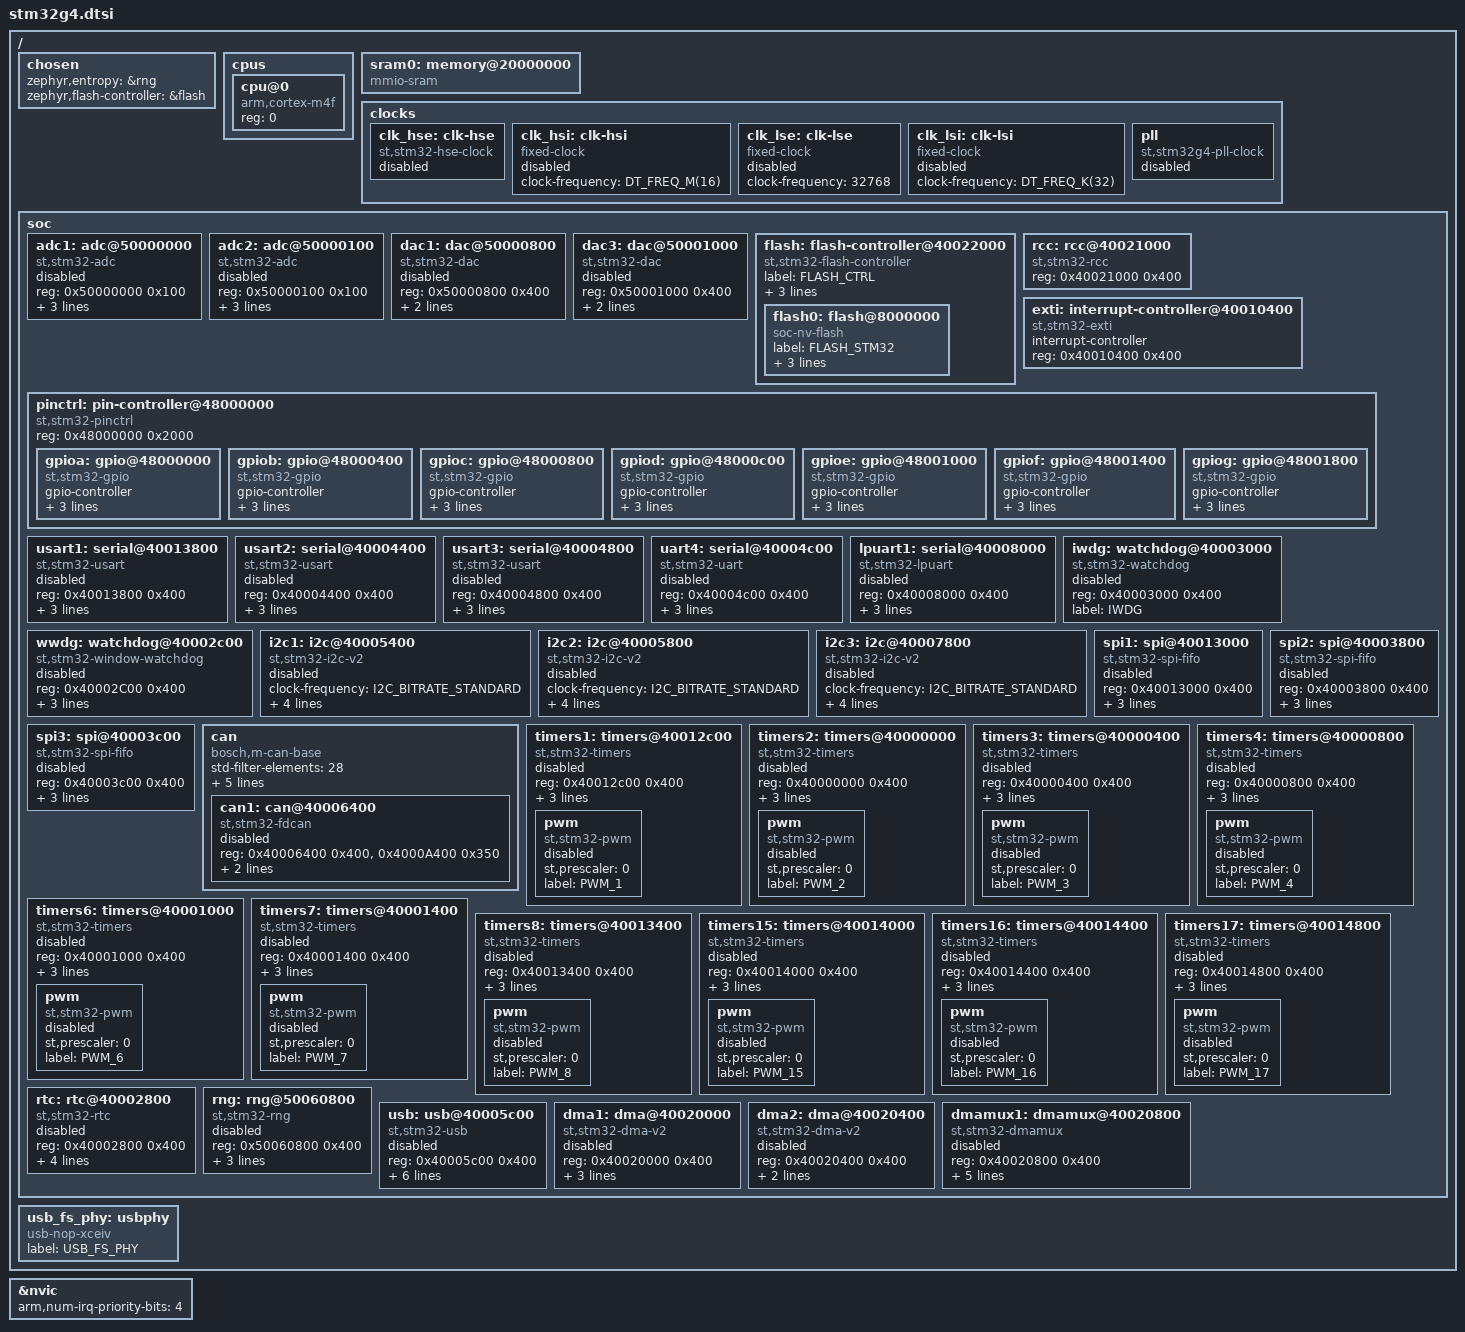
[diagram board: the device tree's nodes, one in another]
/*
 * Copyright (c) 2019 Richard Osterloh <richard.osterloh@gmail.com>
 *
 * SPDX-License-Identifier: Apache-2.0
 */


#include <arm/armv7-m.dtsi>
#include <dt-bindings/clock/stm32_clock.h>
#include <dt-bindings/i2c/i2c.h>
#include <dt-bindings/gpio/gpio.h>
#include <dt-bindings/pwm/pwm.h>
#include <freq.h>

/ {
	chosen {
		zephyr,entropy = &rng;
		zephyr,flash-controller = &flash;
	};

	cpus {
		#address-cells = <1>;
		#size-cells = <0>;

		cpu@0 {
			device_type = "cpu";
			compatible = "arm,cortex-m4f";
			reg = <0>;
		};
	};

	sram0: memory@20000000 {
		compatible = "mmio-sram";
	};

	clocks {
		clk_hse: clk-hse {
			#clock-cells = <0>;
			compatible = "st,stm32-hse-clock";
			status = "disabled";
		};

		clk_hsi: clk-hsi {
			#clock-cells = <0>;
			compatible = "fixed-clock";
			clock-frequency = <DT_FREQ_M(16)>;
			status = "disabled";
		};

		clk_lse: clk-lse {
			#clock-cells = <0>;
			compatible = "fixed-clock";
			clock-frequency = <32768>;
			status = "disabled";
		};

		clk_lsi: clk-lsi {
			#clock-cells = <0>;
			compatible = "fixed-clock";
			clock-frequency = <DT_FREQ_K(32)>;
			status = "disabled";
		};

		pll: pll {
			#clock-cells = <0>;
			compatible = "st,stm32g4-pll-clock";
			status = "disabled";
		};
	};

	soc {
		/*
		 * Both adc instances cannot be used in parallel right now.
		 */
		adc1: adc@50000000 {
			compatible = "st,stm32-adc";
			reg = <0x50000000 0x100>;
			clocks = <&rcc STM32_CLOCK_BUS_AHB2 0x00002000>;
			interrupts = <18 0>;
			status = "disabled";
			label = "ADC_1";
			#io-channel-cells = <1>;
		};

		adc2: adc@50000100 {
			compatible = "st,stm32-adc";
			reg = <0x50000100 0x100>;
			clocks = <&rcc STM32_CLOCK_BUS_AHB2 0x00002000>;
			interrupts = <18 0>;
			status = "disabled";
			label = "ADC_2";
			#io-channel-cells = <1>;
		};

		dac1: dac@50000800 {
			compatible = "st,stm32-dac";
			reg = <0x50000800 0x400>;
			clocks = <&rcc STM32_CLOCK_BUS_AHB2 0x00010000>;
			status = "disabled";
			label = "DAC_1";
			#io-channel-cells = <1>;
		};

		dac3: dac@50001000 {
			compatible = "st,stm32-dac";
			reg = <0x50001000 0x400>;
			clocks = <&rcc STM32_CLOCK_BUS_AHB2 0x00040000>;
			status = "disabled";
			label = "DAC_3";
			#io-channel-cells = <1>;
		};

		flash: flash-controller@40022000 {
			compatible = "st,stm32-flash-controller", "st,stm32g4-flash-controller";
			label = "FLASH_CTRL";
			reg = <0x40022000 0x400>;
			interrupts = <3 0>;
			clocks = <&rcc STM32_CLOCK_BUS_AHB1 0x00000100>;

			#address-cells = <1>;
			#size-cells = <1>;

			flash0: flash@8000000 {
				compatible = "soc-nv-flash";
				label = "FLASH_STM32";

				write-block-size = <8>;
				erase-block-size = <2048>;
				/* maximum erase time(ms) for a 2K sector */
				max-erase-time = <25>;
			};
		};

		rcc: rcc@40021000 {
			compatible = "st,stm32-rcc";
			#clock-cells = <2>;
			reg = <0x40021000 0x400>;
		};

		exti: interrupt-controller@40010400 {
			compatible = "st,stm32-exti";
			interrupt-controller;
			#interrupt-cells = <1>;
			reg = <0x40010400 0x400>;
		};

		pinctrl: pin-controller@48000000 {
			compatible = "st,stm32-pinctrl";
			#address-cells = <1>;
			#size-cells = <1>;
			reg = <0x48000000 0x2000>;

			gpioa: gpio@48000000 {
				compatible = "st,stm32-gpio";
				gpio-controller;
				#gpio-cells = <2>;
				reg = <0x48000000 0x400>;
				clocks = <&rcc STM32_CLOCK_BUS_AHB2 0x00000001>;
				label = "GPIOA";
			};

			gpiob: gpio@48000400 {
				compatible = "st,stm32-gpio";
				gpio-controller;
				#gpio-cells = <2>;
				reg = <0x48000400 0x400>;
				clocks = <&rcc STM32_CLOCK_BUS_AHB2 0x00000002>;
				label = "GPIOB";
			};

			gpioc: gpio@48000800 {
				compatible = "st,stm32-gpio";
				gpio-controller;
				#gpio-cells = <2>;
				reg = <0x48000800 0x400>;
				clocks = <&rcc STM32_CLOCK_BUS_AHB2 0x00000004>;
				label = "GPIOC";
			};

			gpiod: gpio@48000c00 {
				compatible = "st,stm32-gpio";
				gpio-controller;
				#gpio-cells = <2>;
				reg = <0x48000c00 0x400>;
				clocks = <&rcc STM32_CLOCK_BUS_AHB2 0x00000008>;
				label = "GPIOD";
			};

			gpioe: gpio@48001000 {
				compatible = "st,stm32-gpio";
				gpio-controller;
				#gpio-cells = <2>;
				reg = <0x48001000 0x400>;
				clocks = <&rcc STM32_CLOCK_BUS_AHB2 0x00000010>;
				label = "GPIOE";
			};

			gpiof: gpio@48001400 {
				compatible = "st,stm32-gpio";
				gpio-controller;
				#gpio-cells = <2>;
				reg = <0x48001400 0x400>;
				clocks = <&rcc STM32_CLOCK_BUS_AHB2 0x00000020>;
				label = "GPIOF";
			};

			gpiog: gpio@48001800 {
				compatible = "st,stm32-gpio";
				gpio-controller;
				#gpio-cells = <2>;
				reg = <0x48001800 0x400>;
				clocks = <&rcc STM32_CLOCK_BUS_AHB2 0x00000040>;
				label = "GPIOG";
			};
		};

		usart1: serial@40013800 {
			compatible = "st,stm32-usart", "st,stm32-uart";
			reg = <0x40013800 0x400>;
			clocks = <&rcc STM32_CLOCK_BUS_APB2 0x00004000>;
			interrupts = <37 0>;
			status = "disabled";
			label = "UART_1";
		};

		usart2: serial@40004400 {
			compatible = "st,stm32-usart", "st,stm32-uart";
			reg = <0x40004400 0x400>;
			clocks = <&rcc STM32_CLOCK_BUS_APB1 0x00020000>;
			interrupts = <38 0>;
			status = "disabled";
			label = "UART_2";
		};

		usart3: serial@40004800 {
			compatible = "st,stm32-usart", "st,stm32-uart";
			reg = <0x40004800 0x400>;
			clocks = <&rcc STM32_CLOCK_BUS_APB1 0x00040000>;
			interrupts = <39 0>;
			status = "disabled";
			label = "UART_3";
		};

		uart4: serial@40004c00 {
			compatible = "st,stm32-uart";
			reg = <0x40004c00 0x400>;
			clocks = <&rcc STM32_CLOCK_BUS_APB1 0x00080000>;
			interrupts = <52 0>;
			status = "disabled";
			label = "UART_4";
		};

		lpuart1: serial@40008000 {
			compatible = "st,stm32-lpuart", "st,stm32-uart";
			reg = <0x40008000 0x400>;
			clocks = <&rcc STM32_CLOCK_BUS_APB1_2 0x00000001>;
			interrupts = <91 0>;
			status = "disabled";
			label = "LPUART_1";
		};

		iwdg: watchdog@40003000 {
			compatible = "st,stm32-watchdog";
			reg = <0x40003000 0x400>;
			label = "IWDG";
			status = "disabled";
		};

		wwdg: watchdog@40002c00 {
			compatible = "st,stm32-window-watchdog";
			reg = <0x40002C00 0x400>;
			clocks = <&rcc STM32_CLOCK_BUS_APB1 0x00000800>;
			label = "WWDG";
			interrupts = <0 7>;
			status = "disabled";
		};

		i2c1: i2c@40005400 {
			compatible = "st,stm32-i2c-v2";
			clock-frequency = <I2C_BITRATE_STANDARD>;
			#address-cells = <1>;
			#size-cells = <0>;
			reg = <0x40005400 0x400>;
			clocks = <&rcc STM32_CLOCK_BUS_APB1 0x00200000>;
			interrupts = <31 0>, <32 0>;
			interrupt-names = "event", "error";
			status = "disabled";
			label= "I2C_1";
		};

		i2c2: i2c@40005800 {
			compatible = "st,stm32-i2c-v2";
			clock-frequency = <I2C_BITRATE_STANDARD>;
			#address-cells = <1>;
			#size-cells = <0>;
			reg = <0x40005800 0x400>;
			clocks = <&rcc STM32_CLOCK_BUS_APB1 0x00400000>;
			interrupts = <33 0>, <34 0>;
			interrupt-names = "event", "error";
			status = "disabled";
			label= "I2C_2";
		};

		i2c3: i2c@40007800 {
			compatible = "st,stm32-i2c-v2";
			clock-frequency = <I2C_BITRATE_STANDARD>;
			#address-cells = <1>;
			#size-cells = <0>;
			reg = <0x40007800 0x400>;
			clocks = <&rcc STM32_CLOCK_BUS_APB1 0x40000000>;
			interrupts = <92 0>, <93 0>;
			interrupt-names = "event", "error";
			status = "disabled";
			label= "I2C_3";
		};

		spi1: spi@40013000 {
			compatible = "st,stm32-spi-fifo", "st,stm32-spi";
			#address-cells = <1>;
			#size-cells = <0>;
			reg = <0x40013000 0x400>;
			interrupts = <35 5>;
			clocks = <&rcc STM32_CLOCK_BUS_APB2 0x00001000>;
			status = "disabled";
			label = "SPI_1";
		};

		spi2: spi@40003800 {
			compatible = "st,stm32-spi-fifo", "st,stm32-spi";
			#address-cells = <1>;
			#size-cells = <0>;
			reg = <0x40003800 0x400>;
			clocks = <&rcc STM32_CLOCK_BUS_APB1 0x00004000>;
			interrupts = <36 5>;
			status = "disabled";
			label = "SPI_2";
		};

		spi3: spi@40003c00 {
			compatible = "st,stm32-spi-fifo", "st,stm32-spi";
			#address-cells = <1>;
			#size-cells = <0>;
			reg = <0x40003c00 0x400>;
			clocks = <&rcc STM32_CLOCK_BUS_APB1 0x00008000>;
			interrupts = <51 5>;
			status = "disabled";
			label = "SPI_3";
		};

		can {
			compatible = "bosch,m-can-base";
			#address-cells = <1>;
			#size-cells = <1>;
			std-filter-elements = <28>;
			ext-filter-elements = <8>;
			rx-fifo0-elements = <3>;
			rx-fifo1-elements = <3>;
			rx-buffer-elements = <0>;
			tx-buffer-elements = <3>;

			can1: can@40006400 {
				compatible = "st,stm32-fdcan";
				#address-cells = <1>;
				#size-cells = <0>;
				reg = <0x40006400 0x400>, <0x4000A400 0x350>;
				reg-names = "m_can", "message_ram";
				interrupts = <21 0>, <22 0>;
				interrupt-names = "LINE_0", "LINE_1";
				status = "disabled";
				label = "CAN_1";
			};
		};

		timers1: timers@40012c00 {
			compatible = "st,stm32-timers";
			reg = <0x40012c00 0x400>;
			clocks = <&rcc STM32_CLOCK_BUS_APB2 0x00000800>;
			interrupts = <24 0>, <25 0>, <26 0>, <27 0>;
			interrupt-names = "brk", "up", "trgcom", "cc";
			status = "disabled";
			label = "TIMERS_1";

			pwm {
				compatible = "st,stm32-pwm";
				status = "disabled";
				st,prescaler = <0>;
				label = "PWM_1";
				#pwm-cells = <3>;
			};
		};

		timers2: timers@40000000 {
			compatible = "st,stm32-timers";
			reg = <0x40000000 0x400>;
			clocks = <&rcc STM32_CLOCK_BUS_APB1 0x00000001>;
			interrupts = <28 0>;
			interrupt-names = "global";
			status = "disabled";
			label = "TIMERS_2";

			pwm {
				compatible = "st,stm32-pwm";
				status = "disabled";
				st,prescaler = <0>;
				label = "PWM_2";
				#pwm-cells = <3>;
			};
		};

		timers3: timers@40000400 {
			compatible = "st,stm32-timers";
			reg = <0x40000400 0x400>;
			clocks = <&rcc STM32_CLOCK_BUS_APB1 0x00000002>;
			interrupts = <29 0>;
			interrupt-names = "global";
			status = "disabled";
			label = "TIMERS_3";

			pwm {
				compatible = "st,stm32-pwm";
				status = "disabled";
				st,prescaler = <0>;
				label = "PWM_3";
				#pwm-cells = <3>;
			};
		};

		timers4: timers@40000800 {
			compatible = "st,stm32-timers";
			reg = <0x40000800 0x400>;
			clocks = <&rcc STM32_CLOCK_BUS_APB1 0x00000004>;
			interrupts = <30 0>;
			interrupt-names = "global";
			status = "disabled";
			label = "TIMERS_4";

			pwm {
				compatible = "st,stm32-pwm";
				status = "disabled";
				st,prescaler = <0>;
				label = "PWM_4";
				#pwm-cells = <3>;
			};
		};

		timers6: timers@40001000 {
			compatible = "st,stm32-timers";
			reg = <0x40001000 0x400>;
			clocks = <&rcc STM32_CLOCK_BUS_APB1 0x00000010>;
			interrupts = <54 0>;
			interrupt-names = "global";
			status = "disabled";
			label = "TIMERS_6";

			pwm {
				compatible = "st,stm32-pwm";
				status = "disabled";
				st,prescaler = <0>;
				label = "PWM_6";
				#pwm-cells = <3>;
			};
		};

		timers7: timers@40001400 {
			compatible = "st,stm32-timers";
			reg = <0x40001400 0x400>;
			clocks = <&rcc STM32_CLOCK_BUS_APB1 0x00000020>;
			interrupts = <55 0>;
			interrupt-names = "global";
			status = "disabled";
			label = "TIMERS_7";

			pwm {
				compatible = "st,stm32-pwm";
				status = "disabled";
				st,prescaler = <0>;
				label = "PWM_7";
				#pwm-cells = <3>;
			};
		};

		timers8: timers@40013400 {
			compatible = "st,stm32-timers";
			reg = <0x40013400 0x400>;
			clocks = <&rcc STM32_CLOCK_BUS_APB2 0x00002000>;
			interrupts = <43 0>, <44 0>, <45 0>, <46 0>;
			interrupt-names = "brk", "up", "trgcom", "cc";
			status = "disabled";
			label = "TIMERS_8";

			pwm {
				compatible = "st,stm32-pwm";
				status = "disabled";
				st,prescaler = <0>;
				label = "PWM_8";
				#pwm-cells = <3>;
			};
		};

		timers15: timers@40014000 {
			compatible = "st,stm32-timers";
			reg = <0x40014000 0x400>;
			clocks = <&rcc STM32_CLOCK_BUS_APB2 0x00010000>;
			interrupts = <24 0>;
			interrupt-names = "global";
			status = "disabled";
			label = "TIMERS_15";

			pwm {
				compatible = "st,stm32-pwm";
				status = "disabled";
				st,prescaler = <0>;
				label = "PWM_15";
				#pwm-cells = <3>;
			};
		};

		timers16: timers@40014400 {
			compatible = "st,stm32-timers";
			reg = <0x40014400 0x400>;
			clocks = <&rcc STM32_CLOCK_BUS_APB2 0x00020000>;
			interrupts = <25 0>;
			interrupt-names = "global";
			status = "disabled";
			label = "TIMERS_16";

			pwm {
				compatible = "st,stm32-pwm";
				status = "disabled";
				st,prescaler = <0>;
				label = "PWM_16";
				#pwm-cells = <3>;
			};
		};

		timers17: timers@40014800 {
			compatible = "st,stm32-timers";
			reg = <0x40014800 0x400>;
			clocks = <&rcc STM32_CLOCK_BUS_APB2 0x00040000>;
			interrupts = <26 0>;
			interrupt-names = "global";
			status = "disabled";
			label = "TIMERS_17";

			pwm {
				compatible = "st,stm32-pwm";
				status = "disabled";
				st,prescaler = <0>;
				label = "PWM_17";
				#pwm-cells = <3>;
			};
		};

		rtc: rtc@40002800 {
			compatible = "st,stm32-rtc";
			reg = <0x40002800 0x400>;
			interrupts = <41 0>;
			clocks = <&rcc STM32_CLOCK_BUS_APB1 0x00000400>;
			prescaler = <32768>;
			status = "disabled";
			label = "RTC_0";
		};

		rng: rng@50060800 {
			compatible = "st,stm32-rng";
			reg = <0x50060800 0x400>;
			interrupts = <90 0>;
			clocks = <&rcc STM32_CLOCK_BUS_AHB2 0x04000000>;
			status = "disabled";
			label = "RNG";
		};

		usb: usb@40005c00 {
			compatible = "st,stm32-usb";
			reg = <0x40005c00 0x400>;
			interrupts = <20 0>, <19 0>;
			interrupt-names = "usb", "usbhp";
			num-bidir-endpoints = <8>;
			ram-size = <1024>;
			phys = <&usb_fs_phy>;
			clocks = <&rcc STM32_CLOCK_BUS_APB1 0x00800000>;
			status = "disabled";
			label= "USB";
		};

		dma1: dma@40020000 {
			compatible = "st,stm32-dma-v2";
			#dma-cells = <3>;
			reg = <0x40020000 0x400>;
			clocks = <&rcc STM32_CLOCK_BUS_AHB1 0x1>;
			dma-offset = <0>;
			status = "disabled";
			label = "DMA_1";
		};

		dma2: dma@40020400 {
			compatible = "st,stm32-dma-v2";
			#dma-cells = <3>;
			reg = <0x40020400 0x400>;
			clocks = <&rcc STM32_CLOCK_BUS_AHB1 0x2>;
			status = "disabled";
			label = "DMA_2";
		};

		dmamux1: dmamux@40020800 {
			compatible = "st,stm32-dmamux";
			#dma-cells = <3>;
			reg = <0x40020800 0x400>;
			interrupts = <94 0>;
			clocks = <&rcc STM32_CLOCK_BUS_AHB1 0x4>;
			dma-generators = <4>;
			dma-requests= <111>;
			status = "disabled";
			label = "DMAMUX_1";
		};

	};

	usb_fs_phy: usbphy {
		compatible = "usb-nop-xceiv";
		#phy-cells = <0>;
		label = "USB_FS_PHY";
	};
};

&nvic {
	arm,num-irq-priority-bits = <4>;
};
